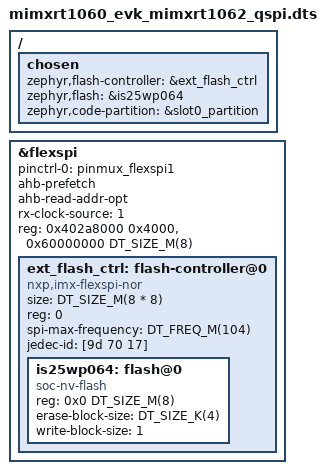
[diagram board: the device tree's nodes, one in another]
/*
 * Copyright 2024 NXP
 *
 * SPDX-License-Identifier: Apache-2.0
 */

#include "mimxrt1060_evk.dtsi"

/ {
	chosen {
		zephyr,flash-controller = &ext_flash_ctrl;
		zephyr,flash = &is25wp064;
		zephyr,code-partition = &slot0_partition;
	};
};

&flexspi {
	status = "okay";
	pinctrl-0 = <&pinmux_flexspi1>;
	pinctrl-names = "default";
	ahb-prefetch;
	ahb-read-addr-opt;
	rx-clock-source = <1>;
	reg = <0x402a8000 0x4000>, <0x60000000 DT_SIZE_M(8)>;

	ext_flash_ctrl: flash-controller@0 {
		compatible = "nxp,imx-flexspi-nor";
		size = <DT_SIZE_M(8 * 8)>;
		reg = <0>;
		spi-max-frequency = <DT_FREQ_M(104)>;
		status = "okay";
		jedec-id = [9d 70 17];

		#address-cells = <1>;
		#size-cells = <1>;
		ranges = <0x0 0x60000000 DT_SIZE_M(8)>;

		is25wp064: flash@0 {
			compatible = "soc-nv-flash";
			reg = <0x0 DT_SIZE_M(8)>;
			erase-block-size = <DT_SIZE_K(4)>;
			write-block-size = <1>;
			#address-cells = <1>;
			#size-cells = <1>;
			ranges;

		};
	};
};
